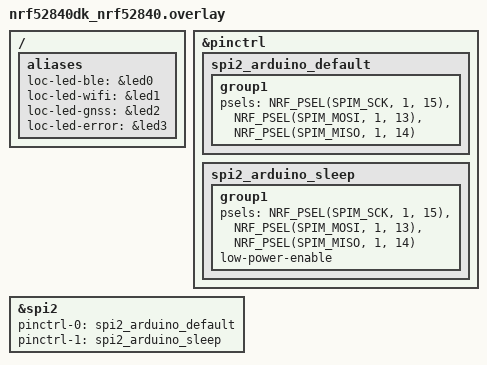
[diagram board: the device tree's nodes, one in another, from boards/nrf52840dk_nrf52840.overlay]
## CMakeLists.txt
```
#
# Copyright (c) 2026 Nordic Semiconductor ASA
#
# SPDX-License-Identifier: LicenseRef-Nordic-5-Clause
#

cmake_minimum_required(VERSION 3.20.0)

# Zephyr CMake project
find_package(Zephyr REQUIRED HINTS $ENV{ZEPHYR_BASE})
project(sidewalk_sid_location)

target_include_directories(app PRIVATE include)
target_sources(app PRIVATE
	src/main.c
	src/app.c
	src/sidewalk.c
)

if(CONFIG_SIDEWALK_USE_PREBUILT_LIBRARIES)
	target_link_libraries(app PRIVATE sidewalk)
endif()
```

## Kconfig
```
#
# Copyright (c) 2026 Nordic Semiconductor ASA
#
# SPDX-License-Identifier: LicenseRef-Nordic-5-Clause
#

mainmenu "Sidewalk location sample"

menu "Sidewalk location sample"

config SID_LOCATION_INTERVAL_S
	int "Location run interval [s]"
	range 10 86400
	default 60
	help
	  Time from the end of the last location run, or from the last
	  message, to the next automatic location run.

endmenu

config SIDEWALK_APPLICATION_NAME
	default "location"

if SIDEWALK_CRYPTO

choice CC3XX_LOCK_VARIANT
	default CC3XX_ATOMIC_LOCK if SOC_NRF52840
endchoice

config PSA_USE_CC3XX_KEY_AGREEMENT_DRIVER
	default n if SOC_NRF52840

config PSA_USE_CC3XX_ASYMMETRIC_SIGNATURE_DRIVER
	default n if SOC_NRF52840

config PSA_USE_CC3XX_ASYMMETRIC_ENCRYPTION_DRIVER
	default n if SOC_NRF52840

config PSA_USE_CC3XX_KEY_MANAGEMENT_DRIVER
	default n if SOC_NRF52840

endif # SIDEWALK_CRYPTO

source "Kconfig.zephyr"
```

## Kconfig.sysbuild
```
#
# Copyright (c) 2026 Nordic Semiconductor ASA
#
# SPDX-License-Identifier: LicenseRef-Nordic-5-Clause
#

choice BOOTLOADER
	default BOOTLOADER_MCUBOOT
endchoice

if BOOTLOADER_MCUBOOT

choice MCUBOOT_MODE
	default MCUBOOT_MODE_OVERWRITE_ONLY
endchoice

config MCUBOOT_SIGNATURE_USING_KMU
	default y if SOC_SERIES_NRF54L

config MCUBOOT_GENERATE_DEFAULT_KEY_FILE
	default y if SOC_SERIES_NRF54L

config MERGED_HEX_FILES
	default y

endif # BOOTLOADER_MCUBOOT

source "${ZEPHYR_BASE}/share/sysbuild/Kconfig"
```

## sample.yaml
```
sample:
  name: Sidewalk location sample
  description: Periodic Amazon Sidewalk location with BLE, Wi-Fi and GNSS methods

common:
  sysbuild: true
  build_only: true
  tags:
    - Sidewalk
    - location

tests:
  sample.sidewalk.location.tag:
    platform_allow:
      - nrf54l15tag/nrf54l15/cpuapp
    integration_platforms:
      - nrf54l15tag/nrf54l15/cpuapp

  sample.sidewalk.location.tag.release:
    platform_allow:
      - nrf54l15tag/nrf54l15/cpuapp
    integration_platforms:
      - nrf54l15tag/nrf54l15/cpuapp
    extra_args:
      - FILE_SUFFIX=release

  sample.sidewalk.location.ble_only:
    build_only: false
    platform_allow:
      - nrf52840dk/nrf52840
      - nrf54l15dk/nrf54l15/cpuapp
      - nrf54lm20dk/nrf54lm20a/cpuapp
      - nrf54lm20dk/nrf54lm20b/cpuapp
    integration_platforms:
      - nrf52840dk/nrf52840
      - nrf54l15dk/nrf54l15/cpuapp
      - nrf54lm20dk/nrf54lm20a/cpuapp
    harness: console
    harness_config:
      type: multi_line
      regex:
        - ".*Booting Sidewalk location.*"

  sample.sidewalk.location.ble_only.release:
    platform_allow:
      - nrf52840dk/nrf52840
      - nrf54l15dk/nrf54l15/cpuapp
      - nrf54lm20dk/nrf54lm20a/cpuapp
      - nrf54lm20dk/nrf54lm20b/cpuapp
    integration_platforms:
      - nrf52840dk/nrf52840
      - nrf54l15dk/nrf54l15/cpuapp
      - nrf54lm20dk/nrf54lm20a/cpuapp
    extra_args:
      - FILE_SUFFIX=release

  sample.sidewalk.location.lr1110:
    build_only: false
    platform_allow:
      - nrf52840dk/nrf52840
    integration_platforms:
      - nrf52840dk/nrf52840
    extra_args:
      - SHIELD="simple_arduino_adapter;semtech_lr1110mb1xxs"
    harness: console
    harness_config:
      type: multi_line
      regex:
        - ".*Booting Sidewalk location.*"

  sample.sidewalk.location.lr1110.release:
    platform_allow:
      - nrf52840dk/nrf52840
    integration_platforms:
      - nrf52840dk/nrf52840
    extra_args:
      - SHIELD="simple_arduino_adapter;semtech_lr1110mb1xxs"
      - FILE_SUFFIX=release

  sample.sidewalk.location.nrf_sidewalk_eb:
    build_only: false
    platform_allow:
      - nrf54l15dk/nrf54l15/cpuapp
      - nrf54lm20dk/nrf54lm20a/cpuapp
      - nrf54lm20dk/nrf54lm20b/cpuapp
    integration_platforms:
      - nrf54l15dk/nrf54l15/cpuapp
      - nrf54lm20dk/nrf54lm20a/cpuapp
    extra_args:
      - SHIELD=nrf_sidewalk_eb
    harness: console
    harness_config:
      type: multi_line
      regex:
        - ".*Booting Sidewalk location.*"

  sample.sidewalk.location.nrf_sidewalk_eb.release:
    platform_allow:
      - nrf54l15dk/nrf54l15/cpuapp
      - nrf54lm20dk/nrf54lm20a/cpuapp
      - nrf54lm20dk/nrf54lm20b/cpuapp
    integration_platforms:
      - nrf54l15dk/nrf54l15/cpuapp
      - nrf54lm20dk/nrf54lm20a/cpuapp
    extra_args:
      - SHIELD=nrf_sidewalk_eb
      - FILE_SUFFIX=release
```

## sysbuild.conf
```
#
# Copyright (c) 2026 Nordic Semiconductor ASA
#
# SPDX-License-Identifier: LicenseRef-Nordic-5-Clause
#

SB_CONFIG_BOOTLOADER_MCUBOOT=y
SB_CONFIG_MCUBOOT_MODE_OVERWRITE_ONLY=y
SB_CONFIG_MCUBOOT_SIGNATURE_USING_KMU=y
SB_CONFIG_MCUBOOT_GENERATE_DEFAULT_KEY_FILE=y
SB_CONFIG_MERGED_HEX_FILES=y
```

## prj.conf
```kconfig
#
# Copyright (c) 2026 Nordic Semiconductor ASA
#
# SPDX-License-Identifier: LicenseRef-Nordic-5-Clause
#
CONFIG_STATIC_INIT_GNU=y

# Sidewalk
CONFIG_SIDEWALK=y
CONFIG_SMF=y
# The sample drives its own LEDs
CONFIG_STATE_NOTIFIER=n

# Log
CONFIG_LOG_BUFFER_SIZE=4096

# Stack and Heap
CONFIG_SYSTEM_WORKQUEUE_STACK_SIZE=4096
CONFIG_MBEDTLS_HEAP_SIZE=4096

# Power Management
CONFIG_PM_DEVICE=y
CONFIG_PM_DEVICE_RUNTIME=y

# Link Time Optimization
CONFIG_LTO=y
CONFIG_ISR_TABLES_LOCAL_DECLARATION=y

# Debug
CONFIG_NCS_APPLICATION_BOOT_BANNER_STRING="Sidewalk location"
CONFIG_SYS_HEAP_RUNTIME_STATS=y
```

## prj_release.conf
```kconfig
#
# Copyright (c) 2026 Nordic Semiconductor ASA
#
# SPDX-License-Identifier: LicenseRef-Nordic-5-Clause
#
CONFIG_STATIC_INIT_GNU=y

# Sidewalk
CONFIG_SIDEWALK=y
CONFIG_SMF=y
# The sample drives its own LEDs
CONFIG_STATE_NOTIFIER=n

# Stack and Heap
CONFIG_SYSTEM_WORKQUEUE_STACK_SIZE=4096
CONFIG_MBEDTLS_HEAP_SIZE=4096

# Disable peripherals
CONFIG_LOG=n
CONFIG_SERIAL=n
CONFIG_CONSOLE=n
CONFIG_UART_CONSOLE=n
CONFIG_BOOT_BANNER=n
CONFIG_NCS_BOOT_BANNER=n
CONFIG_PRINTK=n
CONFIG_ASSERT=n
CONFIG_ASSERT_NO_FILE_INFO=y

# Power Management
CONFIG_PM_DEVICE=y
CONFIG_PM_DEVICE_RUNTIME=y

# Link Time Optimization
CONFIG_LTO=y
CONFIG_ISR_TABLES_LOCAL_DECLARATION=y
```

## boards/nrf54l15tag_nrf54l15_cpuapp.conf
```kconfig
#
# Copyright (c) 2026 Nordic Semiconductor ASA
#
# SPDX-License-Identifier: LicenseRef-Nordic-5-Clause
#

# Console and logs over RTT
CONFIG_USE_SEGGER_RTT=y
CONFIG_CONSOLE=y
CONFIG_RTT_CONSOLE=y
CONFIG_SEGGER_RTT_BUFFER_SIZE_UP=4096
```

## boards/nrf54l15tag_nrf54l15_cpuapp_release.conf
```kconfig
#
# Copyright (c) 2026 Nordic Semiconductor ASA
#
# SPDX-License-Identifier: LicenseRef-Nordic-5-Clause
#

# Replaces nrf54l15tag_nrf54l15_cpuapp.conf, to disable RTT
```

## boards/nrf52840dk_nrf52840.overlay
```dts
/*
 * Copyright (c) 2026 Nordic Semiconductor ASA
 *
 * SPDX-License-Identifier: LicenseRef-Nordic-5-Clause
 */

#include <zephyr/dt-bindings/pinctrl/nrf-pinctrl.h>

/ {
	aliases {
		loc-led-ble = &led0;
		loc-led-wifi = &led1;
		loc-led-gnss = &led2;
		loc-led-error = &led3;
	};
};

/* simple_arduino_adapter borrows spi3_default, which has the H0H1 drive */
&pinctrl {
	spi2_arduino_default: spi2_arduino_default {
		group1 {
			psels = <NRF_PSEL(SPIM_SCK, 1, 15)>,
				<NRF_PSEL(SPIM_MOSI, 1, 13)>,
				<NRF_PSEL(SPIM_MISO, 1, 14)>;
		};
	};

	spi2_arduino_sleep: spi2_arduino_sleep {
		group1 {
			psels = <NRF_PSEL(SPIM_SCK, 1, 15)>,
				<NRF_PSEL(SPIM_MOSI, 1, 13)>,
				<NRF_PSEL(SPIM_MISO, 1, 14)>;
			low-power-enable;
		};
	};
};

&spi2 {
	pinctrl-0 = <&spi2_arduino_default>;
	pinctrl-1 = <&spi2_arduino_sleep>;
};

#include <nrf52840_partitions.dtsi>
```

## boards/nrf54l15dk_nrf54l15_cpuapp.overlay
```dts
/*
 * Copyright (c) 2026 Nordic Semiconductor ASA
 *
 * SPDX-License-Identifier: LicenseRef-Nordic-5-Clause
 */

/ {
	aliases {
		loc-led-ble = &led0;
		loc-led-wifi = &led1;
		loc-led-gnss = &led2;
		loc-led-error = &led3;
	};
};

/* SPI NOR flash is not used */
&spi00 {
	status = "disabled";
};

&mx25r64 {
	status = "disabled";
};

#include <nrf54l15_cpuapp_partitions.dtsi>
```

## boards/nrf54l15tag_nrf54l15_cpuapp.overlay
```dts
/*
 * Copyright (c) 2026 Nordic Semiconductor ASA
 *
 * SPDX-License-Identifier: LicenseRef-Nordic-5-Clause
 */

/ {
	aliases {
		loc-led-ble = &led1_blue;
		loc-led-error = &led1_red;
	};
};

#include <nrf54l15_cpuapp_partitions.dtsi>
```

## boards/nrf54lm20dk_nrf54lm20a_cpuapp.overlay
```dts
/*
 * Copyright (c) 2026 Nordic Semiconductor ASA
 *
 * SPDX-License-Identifier: LicenseRef-Nordic-5-Clause
 */

/ {
	aliases {
		loc-led-ble = &led0;
		loc-led-wifi = &led1;
		loc-led-gnss = &led2;
		loc-led-error = &led3;
	};
};

/* SPI NOR flash is not used */
&spi00 {
	status = "disabled";
};

#include <nrf54lm20_cpuapp_partitions.dtsi>
```

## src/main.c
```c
/*
 * Copyright (c) 2026 Nordic Semiconductor ASA
 *
 * SPDX-License-Identifier: LicenseRef-Nordic-5-Clause
 */

#include <app.h>
#include <sidewalk_version.h>
#include <zephyr/logging/log.h>

int main(void)
{
	PRINT_SIDEWALK_VERSION();
	app_start();
	return 0;
}
```

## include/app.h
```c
/*
 * Copyright (c) 2026 Nordic Semiconductor ASA
 *
 * SPDX-License-Identifier: LicenseRef-Nordic-5-Clause
 */

#ifndef SID_LOCATION_APP_H
#define SID_LOCATION_APP_H

void app_start(void);

#endif /* SID_LOCATION_APP_H */
```

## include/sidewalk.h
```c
/*
 * Copyright (c) 2026 Nordic Semiconductor ASA
 *
 * SPDX-License-Identifier: LicenseRef-Nordic-5-Clause
 */

#ifndef SID_LOCATION_SIDEWALK_H
#define SID_LOCATION_SIDEWALK_H

#include <sid_api.h>
#include <sid_location.h>

#define SIDEWALK_BLE_CONNECT_TIMEOUT_S 30

/* Called from the Sidewalk stack context, must not block */
struct sidewalk_callbacks {
	void (*on_process)(void);
	void (*on_status)(const struct sid_status *status);
	void (*on_location)(const struct sid_location_result *result);
};

int sidewalk_init(const struct sidewalk_callbacks *callbacks);
void sidewalk_process(void);
int sidewalk_start(void);
int sidewalk_stop(void);
void sidewalk_ble_connect_request(void);

int sidewalk_location_init(void);
int sidewalk_location_run_auto(void);
int sidewalk_location_run_level(enum sid_location_effort_mode mode);
enum sid_location_effort_mode sidewalk_location_effort(void);
int sidewalk_location_msg_send(void);

#endif /* SID_LOCATION_SIDEWALK_H */
```

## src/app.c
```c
/*
 * Copyright (c) 2026 Nordic Semiconductor ASA
 *
 * SPDX-License-Identifier: LicenseRef-Nordic-5-Clause
 */

#include <app.h>
#include <sidewalk.h>
#include <sidewalk_dfu/nordic_dfu.h>

#include <buttons.h>
#include <zephyr/drivers/gpio.h>
#include <zephyr/kernel.h>
#include <zephyr/logging/log.h>
#include <zephyr/pm/device_runtime.h>
#include <zephyr/smf.h>

LOG_MODULE_REGISTER(sid_location_app, CONFIG_SIDEWALK_LOG_LEVEL);

enum app_event {
	APP_EVENT_SID_PROCESS,
	APP_EVENT_SID_STATUS,
	APP_EVENT_CYCLE,
	APP_EVENT_BLE_TIMEOUT,
	APP_EVENT_DFU_END,
	APP_EVENT_BUTTON_AUTO,
	APP_EVENT_BUTTON_MSG,
	APP_EVENT_BUTTON_WIFI,
	APP_EVENT_BUTTON_GNSS,
	APP_EVENT_BUTTON_DFU,
	APP_EVENT_LOCATION_RESULT,
};

K_MSGQ_DEFINE(app_msgq, sizeof(enum app_event), 16, 4);

enum app_state {
	APP_STATE_CONNECTING,
	APP_STATE_IDLE,
	APP_STATE_LOCATING,
	APP_STATE_DFU,
};

struct app_ctx {
	struct smf_ctx smf;
	enum app_event event;
	struct sid_status status;
	struct sid_location_result result;
	bool run_pending;
};

static struct app_ctx app;
static const struct smf_state app_states[];

static void app_event_post(enum app_event event)
{
	if (k_msgq_put(&app_msgq, &event, K_NO_WAIT)) {
		LOG_WRN("Event %d dropped, queue full", event);
	}
}

static void cycle_timer_cb(struct k_timer *timer)
{
	ARG_UNUSED(timer);
	app_event_post(APP_EVENT_CYCLE);
}

static K_TIMER_DEFINE(cycle_timer, cycle_timer_cb, NULL);

static void cycle_restart(void)
{
	k_timer_start(&cycle_timer, K_SECONDS(CONFIG_SID_LOCATION_INTERVAL_S), K_NO_WAIT);
}

static void ble_timer_cb(struct k_timer *timer)
{
	ARG_UNUSED(timer);
	app_event_post(APP_EVENT_BLE_TIMEOUT);
}

static K_TIMER_DEFINE(ble_timer, ble_timer_cb, NULL);

static void dfu_check(struct k_work *work)
{
	if (nordic_dfu_is_in_dfu()) {
		(void)k_work_reschedule(k_work_delayable_from_work(work), K_SECONDS(1));
		return;
	}
	app_event_post(APP_EVENT_DFU_END);
}

static K_WORK_DELAYABLE_DEFINE(dfu_check_work, dfu_check);

#define LED_BLINK_MS 100
#define LED_SPEC(alias) GPIO_DT_SPEC_GET_OR(DT_ALIAS(alias), gpios, {0})

enum app_led {
	APP_LED_BLE,
	APP_LED_WIFI,
	APP_LED_GNSS,
	APP_LED_ERROR,
	APP_LED_COUNT,
};

static const struct gpio_dt_spec leds[APP_LED_COUNT] = {
	[APP_LED_BLE] = LED_SPEC(loc_led_ble),
	[APP_LED_WIFI] = LED_SPEC(loc_led_wifi),
	[APP_LED_GNSS] = LED_SPEC(loc_led_gnss),
	[APP_LED_ERROR] = LED_SPEC(loc_led_error),
};

static void leds_off(struct k_work *work)
{
	ARG_UNUSED(work);

	for (int i = 0; i < APP_LED_COUNT; i++) {
		if (leds[i].port) {
			(void)gpio_pin_set_dt(&leds[i], 0);
		}
	}
}

static K_WORK_DELAYABLE_DEFINE(leds_off_work, leds_off);

static void led_blink(enum app_led led)
{
	if (led >= APP_LED_COUNT || !leds[led].port) {
		return;
	}
	(void)gpio_pin_set_dt(&leds[led], 1);
	(void)k_work_reschedule(&leds_off_work, K_MSEC(LED_BLINK_MS));
}

static void on_button(uint32_t event)
{
	app_event_post(event);
}

static int ui_init(void)
{
	for (int i = 0; i < APP_LED_COUNT; i++) {
		if (leds[i].port && (!gpio_is_ready_dt(&leds[i]) ||
				     gpio_pin_configure_dt(&leds[i], GPIO_OUTPUT_INACTIVE))) {
			return -EIO;
		}
	}

	(void)button_set_action_short_press(DK_BTN1, on_button,
					    DT_NODE_EXISTS(DT_ALIAS(sw1)) ? APP_EVENT_BUTTON_AUTO
									  : APP_EVENT_BUTTON_MSG);
	(void)button_set_action_long_press(DK_BTN1, on_button, APP_EVENT_BUTTON_DFU);
	(void)button_set_action(DK_BTN2, on_button, APP_EVENT_BUTTON_MSG);
	(void)button_set_action(DK_BTN3, on_button, APP_EVENT_BUTTON_WIFI);
	(void)button_set_action(DK_BTN4, on_button, APP_EVENT_BUTTON_GNSS);

	return buttons_init();
}

static void on_sidewalk_process(void)
{
	app_event_post(APP_EVENT_SID_PROCESS);
}

static void on_sidewalk_status(const struct sid_status *status)
{
	app.status = *status;
	app_event_post(APP_EVENT_SID_STATUS);
}

static void on_location_result(const struct sid_location_result *result)
{
	app.result = *result;
	app_event_post(APP_EVENT_LOCATION_RESULT);
}

static enum app_led effort_to_led(enum sid_location_effort_mode mode)
{
	switch (mode) {
	case SID_LOCATION_EFFORT_L1:
		return APP_LED_BLE;
	case SID_LOCATION_EFFORT_L3:
		return APP_LED_WIFI;
	case SID_LOCATION_EFFORT_L4:
		return APP_LED_GNSS;
	default:
		return APP_LED_COUNT;
	}
}

static void location_run_started(int err)
{
	if (err) {
		led_blink(APP_LED_ERROR);
		cycle_restart();
		return;
	}

	app.run_pending = false;
	k_timer_stop(&ble_timer);
	smf_set_state(SMF_CTX(&app), &app_states[APP_STATE_LOCATING]);
}

static void location_run_auto(void)
{
	location_run_started(sidewalk_location_run_auto());
}

static void location_start_auto(void)
{
	/* L1 sends nothing that would trigger auto connect, so it needs the link up */
	if (sidewalk_location_effort() == SID_LOCATION_EFFORT_L1 &&
	    !(app.status.detail.link_status_mask & SID_LINK_TYPE_1)) {
		LOG_INF("Location run waits for a Bluetooth LE connection");
		app.run_pending = true;
		sidewalk_ble_connect_request();
		k_timer_start(&ble_timer, K_SECONDS(SIDEWALK_BLE_CONNECT_TIMEOUT_S), K_NO_WAIT);
		return;
	}
	location_run_auto();
}

static void location_ble_timeout(void)
{
	if (!app.run_pending) {
		return;
	}
	app.run_pending = false;
	LOG_WRN("No Bluetooth LE connection");
	location_run_auto();
}

static void location_run_level(enum sid_location_effort_mode mode)
{
	int err = sidewalk_location_run_level(mode);

	if (err == -ENOTSUP) {
		LOG_INF("L%d is not available", mode);
		return;
	}
	location_run_started(err);
}

static void location_msg_send(void)
{
	if (sidewalk_location_msg_send()) {
		led_blink(APP_LED_ERROR);
		return;
	}
	cycle_restart();
}

static void location_msg_result(void)
{
	if (app.result.status == SID_LOCATION_RESOLVE_MSG_SENT) {
		led_blink(APP_LED_BLE);
	} else if (app.result.status == SID_LOCATION_RESOLVE_MSG_TIMEOUT) {
		led_blink(APP_LED_ERROR);
	}
}

static void dfu_start(void)
{
	if (sidewalk_stop()) {
		led_blink(APP_LED_ERROR);
		return;
	}

	int err = nordic_dfu_ble_start();

	if (err) {
		LOG_ERR("DFU start err %d", err);
		led_blink(APP_LED_ERROR);
		(void)sidewalk_start();
		return;
	}
	app.run_pending = false;
	k_timer_stop(&ble_timer);
	k_timer_stop(&cycle_timer);
	(void)k_work_reschedule(&dfu_check_work, K_SECONDS(1));
	smf_set_state(SMF_CTX(&app), &app_states[APP_STATE_DFU]);
}

static enum smf_state_result connecting_run(void *o)
{
	ARG_UNUSED(o);

	if (app.event != APP_EVENT_SID_STATUS || app.status.state != SID_STATE_READY ||
	    app.status.detail.registration_status != SID_STATUS_REGISTERED ||
	    app.status.detail.time_sync_status != SID_STATUS_TIME_SYNCED) {
		return SMF_EVENT_HANDLED;
	}

	if (sidewalk_location_init()) {
		led_blink(APP_LED_ERROR);
		return SMF_EVENT_HANDLED;
	}

	smf_set_state(SMF_CTX(&app), &app_states[APP_STATE_IDLE]);
	cycle_restart();
	return SMF_EVENT_HANDLED;
}

static enum smf_state_result idle_run(void *o)
{
	ARG_UNUSED(o);

	switch (app.event) {
	case APP_EVENT_CYCLE:
	case APP_EVENT_BUTTON_AUTO:
		location_start_auto();
		break;
	case APP_EVENT_BLE_TIMEOUT:
		location_ble_timeout();
		break;
	case APP_EVENT_BUTTON_WIFI:
		location_run_level(SID_LOCATION_EFFORT_L3);
		break;
	case APP_EVENT_BUTTON_GNSS:
		location_run_level(SID_LOCATION_EFFORT_L4);
		break;
	case APP_EVENT_BUTTON_MSG:
		location_msg_send();
		break;
	case APP_EVENT_BUTTON_DFU:
		dfu_start();
		break;
	case APP_EVENT_LOCATION_RESULT:
		if (app.result.status == SID_LOCATION_LVL1_READY) {
			location_start_auto();
			break;
		}
		location_msg_result();
		break;
	case APP_EVENT_SID_STATUS:
		if (app.run_pending && (app.status.detail.link_status_mask & SID_LINK_TYPE_1)) {
			location_run_auto();
		}
		break;
	default:
		break;
	}

	return SMF_EVENT_HANDLED;
}

static enum smf_state_result locating_run(void *o)
{
	ARG_UNUSED(o);
	const struct sid_location_result *result = &app.result;

	switch (app.event) {
	case APP_EVENT_BUTTON_AUTO:
	case APP_EVENT_BUTTON_WIFI:
	case APP_EVENT_BUTTON_GNSS:
	case APP_EVENT_BUTTON_DFU:
		LOG_INF("Location run in progress");
		break;
	case APP_EVENT_BUTTON_MSG:
		location_msg_send();
		break;
	case APP_EVENT_LOCATION_RESULT:
		LOG_INF("Location status %d, err %d, effort %d, link 0x%x", result->status,
			(int)result->err, result->mode, result->link);
		location_msg_result();
		if (result->status != SID_LOCATION_SCAN_AND_SEND_DONE) {
			break;
		}
		led_blink(result->err == SID_ERROR_NONE ? effort_to_led(result->mode)
							: APP_LED_ERROR);
		smf_set_state(SMF_CTX(&app), &app_states[APP_STATE_IDLE]);
		break;
	default:
		break;
	}

	return SMF_EVENT_HANDLED;
}

static void locating_exit(void *o)
{
	ARG_UNUSED(o);
	cycle_restart();
}

static enum smf_state_result dfu_run(void *o)
{
	ARG_UNUSED(o);

	switch (app.event) {
	case APP_EVENT_BUTTON_DFU:
		if (nordic_dfu_is_in_dfu()) {
			(void)nordic_dfu_ble_stop();
		}
		smf_set_state(SMF_CTX(&app), &app_states[APP_STATE_IDLE]);
		break;
	case APP_EVENT_DFU_END:
		smf_set_state(SMF_CTX(&app), &app_states[APP_STATE_IDLE]);
		break;
	default:
		break;
	}

	return SMF_EVENT_HANDLED;
}

static void dfu_exit(void *o)
{
	ARG_UNUSED(o);

	(void)k_work_cancel_delayable(&dfu_check_work);
	(void)k_work_reschedule(&leds_off_work, K_NO_WAIT);

	if (sidewalk_start()) {
		led_blink(APP_LED_ERROR);
	}
	cycle_restart();
}

static const struct smf_state app_states[] = {
	[APP_STATE_CONNECTING] = SMF_CREATE_STATE(NULL, connecting_run, NULL, NULL, NULL),
	[APP_STATE_IDLE] = SMF_CREATE_STATE(NULL, idle_run, NULL, NULL, NULL),
	[APP_STATE_LOCATING] = SMF_CREATE_STATE(NULL, locating_run, locating_exit, NULL, NULL),
	[APP_STATE_DFU] = SMF_CREATE_STATE(NULL, dfu_run, dfu_exit, NULL, NULL),
};

static void sidewalk_thread_entry(void *p1, void *p2, void *p3)
{
	ARG_UNUSED(p1);
	ARG_UNUSED(p2);
	ARG_UNUSED(p3);

	static const struct sidewalk_callbacks callbacks = {
		.on_process = on_sidewalk_process,
		.on_status = on_sidewalk_status,
		.on_location = on_location_result,
	};

	if (sidewalk_init(&callbacks)) {
		led_blink(APP_LED_ERROR);
		return;
	}

	LOG_INF("Waiting for Sidewalk registration and time sync");
	smf_set_initial(SMF_CTX(&app), &app_states[APP_STATE_CONNECTING]);

	while (true) {
		k_msgq_get(&app_msgq, &app.event, K_FOREVER);

		if (app.event == APP_EVENT_SID_PROCESS) {
			sidewalk_process();
			continue;
		}
		smf_run_state(SMF_CTX(&app));
	}
}

static struct k_thread sidewalk_thread;
static K_THREAD_STACK_DEFINE(sidewalk_thread_stack, CONFIG_SIDEWALK_THREAD_STACK_SIZE);

void app_start(void)
{
#if defined(CONFIG_UART_CONSOLE)
	(void)pm_device_runtime_disable(DEVICE_DT_GET(DT_CHOSEN(zephyr_console)));
#endif

	if (ui_init()) {
		LOG_ERR("UI init failed");
	}

	(void)k_thread_create(&sidewalk_thread, sidewalk_thread_stack,
			      K_THREAD_STACK_SIZEOF(sidewalk_thread_stack), sidewalk_thread_entry,
			      NULL, NULL, NULL, CONFIG_SIDEWALK_THREAD_PRIORITY, 0, K_NO_WAIT);
	(void)k_thread_name_set(&sidewalk_thread, "sidewalk");
}
```

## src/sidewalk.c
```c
/*
 * Copyright (c) 2026 Nordic Semiconductor ASA
 *
 * SPDX-License-Identifier: LicenseRef-Nordic-5-Clause
 */

#include <sidewalk.h>

#include <app_ble_config.h>
#include <app_mfg_config.h>
#include <app_subGHz_config.h>
#include <bt_app_callbacks.h>
#include <json_printer/sidTypes2str.h>
#include <sid_hal_reset_ifc.h>
#include <sid_pal_common_ifc.h>
#ifdef CONFIG_SIDEWALK_SUBGHZ_SUPPORT
#include <sid_pal_radio_ifc.h>
#endif /* CONFIG_SIDEWALK_SUBGHZ_SUPPORT */
#ifdef CONFIG_SIDEWALK_SUBGHZ_RADIO_LR1110
#include <app_location_lr11xx_config.h>
#endif /* CONFIG_SIDEWALK_SUBGHZ_RADIO_LR1110 */

#include <stdio.h>
#include <zephyr/bluetooth/conn.h>
#include <zephyr/logging/log.h>

LOG_MODULE_DECLARE(sid_location_app, CONFIG_SIDEWALK_LOG_LEVEL);

#ifdef CONFIG_SIDEWALK_SUBGHZ_SUPPORT
#define APP_LINK_MASK (SID_LINK_TYPE_1 | SID_LINK_TYPE_3)
#else
#define APP_LINK_MASK (SID_LINK_TYPE_1)
#endif /* CONFIG_SIDEWALK_SUBGHZ_SUPPORT */

#ifdef CONFIG_SIDEWALK_SUBGHZ_REGION_EU868
#define APP_SUBGHZ_REGION SID_PAL_RADIO_RC_EU
#else
#define APP_SUBGHZ_REGION SID_PAL_RADIO_RC_NA
#endif /* CONFIG_SIDEWALK_SUBGHZ_REGION_EU868 */

#ifdef CONFIG_SIDEWALK_SUBGHZ_RADIO_LR1110
#define APP_LOCATION_METHODS                                                                       \
	(SID_LOCATION_METHOD_GATEWAY | SID_LOCATION_METHOD_WIFI | SID_LOCATION_METHOD_GNSS)
#define APP_LOCATION_MAX_EFFORT SID_LOCATION_EFFORT_L4
#define APP_LOCATION_AUTO_MODE	SID_LOCATION_EFFORT_DEFAULT
#else
#define APP_LOCATION_METHODS	SID_LOCATION_METHOD_GATEWAY
#define APP_LOCATION_MAX_EFFORT SID_LOCATION_EFFORT_L1
#define APP_LOCATION_AUTO_MODE	SID_LOCATION_EFFORT_L1
#endif /* CONFIG_SIDEWALK_SUBGHZ_RADIO_LR1110 */

static struct sid_handle *handle;
static const struct sidewalk_callbacks *app_callbacks;

static void on_sidewalk_event(bool in_isr, void *context)
{
	ARG_UNUSED(in_isr);
	ARG_UNUSED(context);
	app_callbacks->on_process();
}

static void on_sidewalk_status_changed(const struct sid_status *status, void *context)
{
	ARG_UNUSED(context);

	LOG_INF("Sidewalk state %d, registered %d, time synced %d, links 0x%x", status->state,
		status->detail.registration_status == SID_STATUS_REGISTERED,
		status->detail.time_sync_status == SID_STATUS_TIME_SYNCED,
		status->detail.link_status_mask);
	app_callbacks->on_status(status);
}

static void on_sidewalk_msg_received(const struct sid_msg_desc *msg_desc, const struct sid_msg *msg,
				     void *context)
{
	ARG_UNUSED(msg_desc);
	ARG_UNUSED(msg);
	ARG_UNUSED(context);
}

static void on_sidewalk_msg_sent(const struct sid_msg_desc *msg_desc, void *context)
{
	ARG_UNUSED(msg_desc);
	ARG_UNUSED(context);
}

static void on_sidewalk_send_error(sid_error_t error, const struct sid_msg_desc *msg_desc,
				   void *context)
{
	ARG_UNUSED(msg_desc);
	ARG_UNUSED(context);
	LOG_WRN("Send error %d (%s)", (int)error, SID_ERROR_T_STR(error));
}

static void on_sidewalk_factory_reset(void *context)
{
	ARG_UNUSED(context);

	LOG_INF("Factory reset done, rebooting");
	if (sid_hal_reset(SID_HAL_RESET_NORMAL)) {
		LOG_WRN("Cannot reboot");
	}
}

static void on_location_update(const struct sid_location_result *const result, void *context)
{
	ARG_UNUSED(context);
	app_callbacks->on_location(result);
}

#ifdef CONFIG_SIDEWALK_SUBGHZ_SUPPORT
static sid_pal_radio_rx_packet_t radio_rx_packet;

static void radio_event_notifier(sid_pal_radio_events_t event)
{
	ARG_UNUSED(event);
}

static void radio_irq_handler(void)
{
}
#endif /* CONFIG_SIDEWALK_SUBGHZ_SUPPORT */

static int platform_init(void)
{
	platform_parameters_t platform_parameters = {
		.mfg_store_region.addr_start = APP_MFG_CFG_FLASH_START,
		.mfg_store_region.addr_end = APP_MFG_CFG_FLASH_END,
#ifdef CONFIG_SIDEWALK_SUBGHZ_SUPPORT
		.platform_init_parameters.radio_cfg = get_radio_cfg(),
		.platform_init_parameters.region = APP_SUBGHZ_REGION,
		.platform_init_parameters.sub_ghz_cfg = app_get_sub_ghz_config(),
#ifdef CONFIG_SIDEWALK_SUBGHZ_RADIO_LR1110
		.platform_init_parameters.gnss_wifi_cfg =
			(lr11xx_gnss_wifi_config_t *)get_location_cfg(),
#endif /* CONFIG_SIDEWALK_SUBGHZ_RADIO_LR1110 */
#endif /* CONFIG_SIDEWALK_SUBGHZ_SUPPORT */
	};

	sid_error_t err = sid_platform_init(&platform_parameters);

	if (err) {
		LOG_ERR("Sidewalk platform init err %d (%s)", (int)err, SID_ERROR_T_STR(err));
		return -EIO;
	}

	if (app_mfg_cfg_is_empty()) {
		LOG_ERR("No manufacturing data at 0x%08x, provision the device",
			APP_MFG_CFG_FLASH_START);
		return -ENODATA;
	}

#ifdef CONFIG_SIDEWALK_SUBGHZ_SUPPORT
	int32_t radio_err =
		sid_pal_radio_init(radio_event_notifier, radio_irq_handler, &radio_rx_packet);

	if (radio_err) {
		LOG_ERR("Radio init err %d", radio_err);
		return -EIO;
	}
	(void)sid_pal_radio_sleep(0);
#endif /* CONFIG_SIDEWALK_SUBGHZ_SUPPORT */

	return 0;
}

/* The Sidewalk and SMP services are always registered, each identity may use only its own */
static bool gatt_authorize(struct bt_conn *conn, const struct bt_gatt_attr *attr)
{
	struct bt_conn_info info;

	if (bt_conn_get_info(conn, &info)) {
		return false;
	}
	if (info.id == BT_ID_SIDEWALK) {
		return !sid_ble_bt_attr_is_SMP(attr);
	}
	if (info.id == BT_ID_SMP_DFU) {
		return !sid_ble_bt_attr_is_SIDEWALK(attr);
	}
	return true;
}

static const struct bt_gatt_authorization_cb gatt_authorization = {
	.read_authorize = gatt_authorize,
	.write_authorize = gatt_authorize,
};

int sidewalk_init(const struct sidewalk_callbacks *callbacks)
{
	static struct sid_event_callbacks sid_callbacks = {
		.on_event = on_sidewalk_event,
		.on_msg_received = on_sidewalk_msg_received,
		.on_msg_sent = on_sidewalk_msg_sent,
		.on_send_error = on_sidewalk_send_error,
		.on_status_changed = on_sidewalk_status_changed,
		.on_factory_reset = on_sidewalk_factory_reset,
	};
	struct sid_config config = {
		.link_mask = APP_LINK_MASK,
		.dev_ch = {
			.type = SID_END_DEVICE_TYPE_STATIC,
			.power_type = SID_END_DEVICE_POWERED_BY_BATTERY_AND_LINE_POWER,
			.qualification_id = 0x0001,
		},
		.callbacks = &sid_callbacks,
		.link_config = app_get_ble_config(),
		.sub_ghz_link_config = app_get_sub_ghz_config(),
	};

	app_callbacks = callbacks;

	int ret = platform_init();

	if (ret) {
		return ret;
	}

	if (bt_gatt_authorization_cb_register(&gatt_authorization)) {
		LOG_ERR("GATT authorization register failed");
		return -EIO;
	}

	sid_error_t err = sid_init(&config, &handle);

	if (err) {
		LOG_ERR("Sidewalk init err %d (%s)", (int)err, SID_ERROR_T_STR(err));
		return -EIO;
	}

	ret = sidewalk_start();
	if (ret) {
		return ret;
	}

	enum sid_link_connection_policy policy = SID_LINK_CONNECTION_POLICY_AUTO_CONNECT;
	struct sid_link_auto_connect_params params = {
		.link_type = SID_LINK_TYPE_1,
		.enable = true,
		.connection_attempt_timeout_seconds = SIDEWALK_BLE_CONNECT_TIMEOUT_S,
	};

	(void)sid_option(handle, SID_OPTION_SET_LINK_CONNECTION_POLICY, &policy, sizeof(policy));
	(void)sid_option(handle, SID_OPTION_SET_LINK_POLICY_AUTO_CONNECT_PARAMS, &params,
			 sizeof(params));

	return 0;
}

void sidewalk_process(void)
{
	(void)sid_process(handle);
}

int sidewalk_start(void)
{
	sid_error_t err = sid_start(handle, APP_LINK_MASK);

	if (err) {
		LOG_ERR("Sidewalk start err %d (%s)", (int)err, SID_ERROR_T_STR(err));
		return -EIO;
	}
	return 0;
}

int sidewalk_stop(void)
{
	sid_error_t err = sid_stop(handle, APP_LINK_MASK);

	if (err) {
		LOG_ERR("Sidewalk stop err %d (%s)", (int)err, SID_ERROR_T_STR(err));
		return -EIO;
	}
	return 0;
}

void sidewalk_ble_connect_request(void)
{
	(void)sid_ble_bcn_connection_request(handle, true);
}

int sidewalk_location_init(void)
{
	struct sid_location_config config = {
		.sid_location_type_mask = APP_LOCATION_METHODS,
		.max_effort = APP_LOCATION_MAX_EFFORT,
		.manage_effort = true,
		.callbacks = {
			.on_update = on_location_update,
		},
		.auto_link_pause_resume = IS_ENABLED(CONFIG_SIDEWALK_SUBGHZ_SUPPORT),
	};

	sid_error_t err = sid_location_init(handle, &config);

	if (err) {
		LOG_ERR("Location init err %d (%s)", (int)err, SID_ERROR_T_STR(err));
		return -EIO;
	}
	return 0;
}

static int location_run(struct sid_location_run_config *config)
{
	sid_error_t err = sid_location_run(handle, config, 0);

	if (err) {
		LOG_ERR("Location run err %d (%s)", (int)err, SID_ERROR_T_STR(err));
		return -EIO;
	}
	LOG_INF("Location run started at L%d", sid_location_get_effort_mode(handle));
	return 0;
}

int sidewalk_location_run_auto(void)
{
	struct sid_location_run_config config = {
		.mode = APP_LOCATION_AUTO_MODE,
		.type = SID_LOCATION_SCAN_AND_SEND,
	};

	return location_run(&config);
}

int sidewalk_location_run_level(enum sid_location_effort_mode mode)
{
	struct sid_location_run_config config = {
		.type = SID_LOCATION_SCAN_AND_SEND,
		.levels = {mode},
		.num_levels = 1,
	};

	if (!IS_ENABLED(CONFIG_SIDEWALK_SUBGHZ_RADIO_LR1110)) {
		return -ENOTSUP;
	}
	return location_run(&config);
}

enum sid_location_effort_mode sidewalk_location_effort(void)
{
	return sid_location_get_effort_mode(handle);
}

int sidewalk_location_msg_send(void)
{
	static unsigned int counter;
	char text[24];
	struct sid_msg msg = {
		.data = text,
		.size = snprintf(text, sizeof(text), "Message %u", ++counter),
	};
	struct sid_msg_desc desc = {
		.type = SID_MSG_TYPE_NOTIFY,
		.link_type = SID_LINK_TYPE_1,
		.link_mode = SID_LINK_MODE_CLOUD,
		.msg_desc_attr.tx_attr.resolve_location = SID_TX_LOCATION_LINK_RESOLVE,
	};

	sid_error_t err = sid_put_msg(handle, &msg, &desc);

	if (err) {
		LOG_ERR("Message err %d (%s)", (int)err, SID_ERROR_T_STR(err));
		return -EIO;
	}
	LOG_INF("\"%s\" with location resolution queued", text);
	return 0;
}
```
